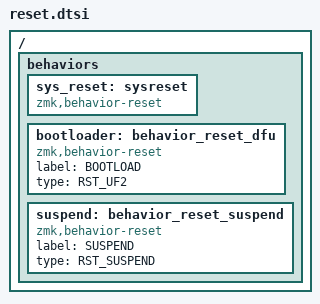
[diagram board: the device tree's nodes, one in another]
/*
 * Copyright (c) 2020 The ZMK Contributors
 *
 * SPDX-License-Identifier: MIT
 */

#include <dt-bindings/zmk/reset.h>

/ {
    behaviors {
        // Behavior can be invoked on peripherals, so name must be <= 8 characters.
        sys_reset: sysreset {
            compatible = "zmk,behavior-reset";
            #binding-cells = <0>;
        };

		bootloader: behavior_reset_dfu {
			compatible = "zmk,behavior-reset";
			label = "BOOTLOAD";
			type = <RST_UF2>;
			#binding-cells = <0>;
		};
		suspend: behavior_reset_suspend {
			compatible = "zmk,behavior-reset";
			label = "SUSPEND";
			type = <RST_SUSPEND>;
			#binding-cells = <0>;
		};
	};
};
